AUTOSAR XML (schema 314)
package /ComponentType
  internal behavior Sa_HwTrq2_InternalBehavior: component=Sa_HwTrq2
    4 x timing event:
      HwTrq2_Init1_InitEvent: start-on-event=HwTrq2_Init1, period=0
      TMT_HwTrq2_Per1: start-on-event=HwTrq2_Per1, period=0.002
      TMT_HwTrq2_Per2: start-on-event=HwTrq2_Per2, period=0.004
      TMT_HwTrq2_Per3: start-on-event=HwTrq2_Per3, period=0.1
    port-api-options:
      enable-take-address=false, indirect-api=false, port=AnaDiffHwTrq
      enable-take-address=false, indirect-api=false, port=AnaHwTorque
      enable-take-address=false, indirect-api=false, port=HwTrq2_Per3_CP0
      enable-take-address=false, indirect-api=false, port=HwTrqScaleVal
      enable-take-address=false, indirect-api=false, port=NxtrDiagMgr
      enable-take-address=false, indirect-api=false, port=SysCHwTorqueSqd
      enable-take-address=false, indirect-api=false, port=SysCT1ADC
      enable-take-address=false, indirect-api=false, port=SysCT2ADC
      enable-take-address=false, indirect-api=false, port=T1TrimVal
      enable-take-address=false, indirect-api=false, port=T2TrimVal
    4 x runnable:
      HwTrq2_Init1
      HwTrq2_Per1
        5 x data read access:
          READ_HwTrqScaleVal_VoltsPerDeg_f32: data-element=HwTrqScaleVal.VoltsPerDeg_f32
          READ_SysCT1ADC_Volt_f32: data-element=SysCT1ADC.Volt_f32
          READ_SysCT2ADC_Volt_f32: data-element=SysCT2ADC.Volt_f32
          READ_T1TrimVal_Volt_f32: data-element=T1TrimVal.Volt_f32
          READ_T2TrimVal_Volt_f32: data-element=T2TrimVal.Volt_f32
        data write access WRITE_SysCHwTorqueSqd_HwNmSq_f32: data-element=SysCHwTorqueSqd.HwNmSq_f32
      HwTrq2_Per2
        5 x data read access:
          READ_AnaHwTorque_HwNm_f32: data-element=AnaHwTorque.HwNm_f32
          READ_SysCT1ADC_Volt_f32: data-element=SysCT1ADC.Volt_f32
          READ_SysCT2ADC_Volt_f32: data-element=SysCT2ADC.Volt_f32
          READ_T1TrimVal_Volt_f32: data-element=T1TrimVal.Volt_f32
          READ_T2TrimVal_Volt_f32: data-element=T2TrimVal.Volt_f32
        sync call SC_NxtrDiagMgr_SetNTCStatus: operation=NxtrDiagMgr.SetNTCStatus, timeout=0
      HwTrq2_Per3
        data read access READ_AnaDiffHwTrq_Volt_f32: data-element=AnaDiffHwTrq.Volt_f32
        sync call SC_HwTrq2_Per3_CP0_CheckpointReached: operation=HwTrq2_Per3_CP0.CheckpointReached, timeout=0
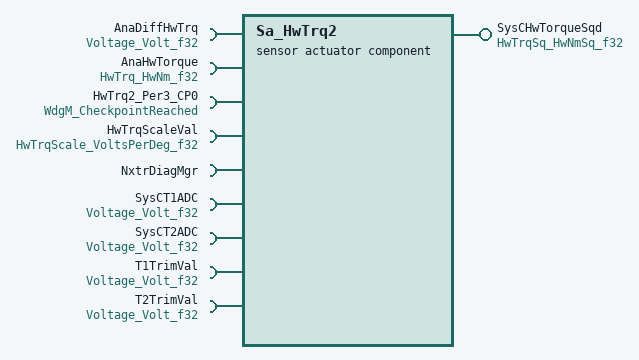
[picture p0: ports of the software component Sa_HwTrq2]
  sensor actuator software component type Sa_HwTrq2
    provide port SysCHwTorqueSqd: unqueued-sender-com-spec{data-element=HwNmSq_f32, can-invalidate=false, init-value=D_ZERO_ULS_F32}, provided-interface=HwTrqSq_HwNmSq_f32
    9 x require port:
      AnaDiffHwTrq: unqueued-receiver-com-spec{data-element=Volt_f32, init-value=D_ZERO_ULS_F32}, required-interface=Voltage_Volt_f32
      AnaHwTorque: unqueued-receiver-com-spec{data-element=HwNm_f32, init-value=D_ZERO_ULS_F32}, required-interface=HwTrq_HwNm_f32
      HwTrq2_Per3_CP0: client-com-spec=CheckpointReached, required-interface=WdgM_CheckpointReached
      HwTrqScaleVal: unqueued-receiver-com-spec{data-element=VoltsPerDeg_f32, init-value=D_ZERO_ULS_F32}, required-interface=HwTrqScale_VoltsPerDeg_f32
      NxtrDiagMgr: required-com-specs=[GetNTCActive, GetNTCFailed, GetNTCStatus, SetNTCStatus], required-interface=NxtrDiagMgr
      SysCT1ADC: unqueued-receiver-com-spec{data-element=Volt_f32, init-value=D_ZERO_ULS_F32}, required-interface=Voltage_Volt_f32
      SysCT2ADC: unqueued-receiver-com-spec{data-element=Volt_f32, init-value=D_ZERO_ULS_F32}, required-interface=Voltage_Volt_f32
      T1TrimVal: unqueued-receiver-com-spec{data-element=Volt_f32, init-value=D_ZERO_ULS_F32}, required-interface=Voltage_Volt_f32
      T2TrimVal: unqueued-receiver-com-spec{data-element=Volt_f32, init-value=D_ZERO_ULS_F32}, required-interface=Voltage_Volt_f32
  swc implementation Sa_HwTrq2_Implementation: behavior=Sa_HwTrq2_InternalBehavior
    code-descriptors:
      code Code: type=SRC
